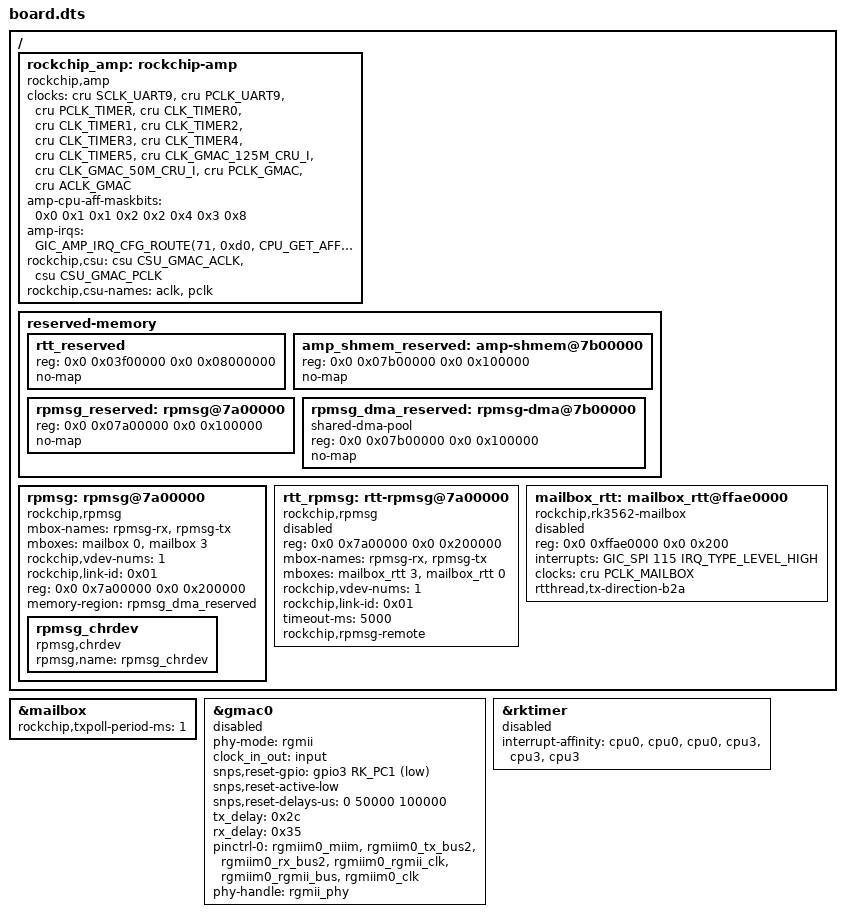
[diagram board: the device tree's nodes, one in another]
/**
 * RT-Thread RuiChing
 *
 * COPYRIGHT (C) 2024-2025 Shanghai Real-Thread Electronic Technology Co., Ltd.
 * All rights reserved.
 *
 * The license and distribution terms for this file may be
 * found in the file LICENSE in this distribution.
 */
/dts-v1/;
#include "rc-pi-3562-v1_0.dtsi"

/ {

	rockchip_amp: rockchip-amp {
		compatible = "rockchip,amp";
		clocks = <&cru SCLK_UART9>, <&cru PCLK_UART9>,
		        <&cru PCLK_TIMER>, <&cru CLK_TIMER0>, <&cru CLK_TIMER1>, <&cru CLK_TIMER2>, 
				<&cru CLK_TIMER3>, <&cru CLK_TIMER4>, <&cru CLK_TIMER5>,
				<&cru CLK_GMAC_125M_CRU_I>, <&cru CLK_GMAC_50M_CRU_I>,
			 	<&cru PCLK_GMAC>, <&cru ACLK_GMAC>;
		amp-cpu-aff-maskbits = /bits/ 64 <0x0 0x1 0x1 0x2 0x2 0x4 0x3 0x8>;
		amp-irqs = /bits/ 64 <
			GIC_AMP_IRQ_CFG_ROUTE(71, 0xd0, CPU_GET_AFFINITY(3, 0))   // UART9_IRQn
			GIC_AMP_IRQ_CFG_ROUTE(102, 0xd0, CPU_GET_AFFINITY(3, 0))   // gmacirq
			GIC_AMP_IRQ_CFG_ROUTE(105, 0xd0, CPU_GET_AFFINITY(3, 0))   // gmacirq
            GIC_AMP_IRQ_CFG_ROUTE(147, 0xd0, CPU_GET_AFFINITY(3, 0))   // mailbox_bb
            GIC_AMP_IRQ_CFG_ROUTE(77, 0xd0, CPU_GET_AFFINITY(0, 0))   // timer0
            GIC_AMP_IRQ_CFG_ROUTE(78, 0xd0, CPU_GET_AFFINITY(0, 0))   // timer1
            GIC_AMP_IRQ_CFG_ROUTE(79, 0xd0, CPU_GET_AFFINITY(0, 0))   // timer2
            GIC_AMP_IRQ_CFG_ROUTE(80, 0xd0, CPU_GET_AFFINITY(3, 0))   // timer3
            GIC_AMP_IRQ_CFG_ROUTE(81, 0xd0, CPU_GET_AFFINITY(3, 0))   // timer4
            GIC_AMP_IRQ_CFG_ROUTE(82, 0xd0, CPU_GET_AFFINITY(3, 0))   // timer5
		>;

		rockchip,csu = <&csu CSU_GMAC_ACLK>, <&csu CSU_GMAC_PCLK>;
		rockchip,csu-names = "aclk", "pclk";

		status = "okay";
	};

	reserved-memory {
		#address-cells = <2>;
		#size-cells = <2>;
		ranges;

		/* remote amp core address */
		rtt_reserved {
			reg = <0x0 0x03f00000 0x0 0x08000000>;
			no-map;
		};

		/* remote amp core address */
		amp_shmem_reserved: amp-shmem@7b00000 {
			reg = <0x0 0x07b00000 0x0 0x100000>;
			no-map;
		};
		rpmsg_reserved: rpmsg@7a00000 {
			reg = <0x0 0x07a00000 0x0 0x100000>;
			no-map;
		};
		rpmsg_dma_reserved: rpmsg-dma@7b00000 {
			compatible = "shared-dma-pool";
			reg = <0x0 0x07b00000 0x0 0x100000>;
			no-map;
		};

	};

	rpmsg: rpmsg@7a00000 {
		compatible = "rockchip,rpmsg";
		mbox-names = "rpmsg-rx", "rpmsg-tx";
		mboxes = <&mailbox 0 &mailbox 3>;
		rockchip,vdev-nums = <1>;
		/* CPU3: link-id 0x03; MCU: link-id 0x04; */
		rockchip,link-id = <0x01>;
		// reg = <0x0 0x7c00000 0x0 0x20000>;
		reg = <0x0 0x7a00000 0x0 0x200000>;
		memory-region = <&rpmsg_dma_reserved>;
		status = "okay";

        rpmsg_chrdev {
            compatible = "rpmsg,chrdev";
            rpmsg,name = "rpmsg_chrdev";
            status = "okay";
        };
	};

	rtt_rpmsg: rtt-rpmsg@7a00000 {
		compatible = "rockchip,rpmsg";
		// reg = <0x3a00000 0x020000>;
		reg = <0x0 0x7a00000 0x0 0x200000>;
		mbox-names = "rpmsg-rx", "rpmsg-tx";
		// mboxes = <&mailbox2_amp 0 &mailbox0_amp 0>;
		mboxes = <&mailbox_rtt 3 &mailbox_rtt 0>;
		rockchip,vdev-nums = <1>;
		/* CPU2: link-id 0x02; */
		rockchip,link-id = <0x01>;
		timeout-ms = <5000>;
		status = "okay,rtt";
		rockchip,rpmsg-remote;
    };

	mailbox_rtt: mailbox_rtt@ffae0000 {
		compatible = "rockchip,rk3562-mailbox",
			     "rockchip,rk3368-mailbox";
		reg = <0x0 0xffae0000 0x0 0x200>;
		interrupts = <GIC_SPI 115 IRQ_TYPE_LEVEL_HIGH>;
		clocks = <&cru PCLK_MAILBOX>;
		clock-names = "pclk_mailbox";
		#mbox-cells = <1>;
		rtthread,tx-direction-b2a;
		status = "okay,rtt";
	};

};

&mailbox {
	rockchip,txpoll-period-ms = <1>;
	status = "okay";
};

&gmac0 {
	phy-mode = "rgmii";
	clock_in_out = "input";

	snps,reset-gpio = <&gpio3 RK_PC1 GPIO_ACTIVE_LOW>;
	snps,reset-active-low;
	/* Reset time is 20ms, 100ms for rtl8211f */
	snps,reset-delays-us = <0 50000 100000>;

	tx_delay = <0x2c>;
	rx_delay = <0x35>;

	pinctrl-names = "default";
	pinctrl-0 = <&rgmiim0_miim
		     &rgmiim0_tx_bus2
		     &rgmiim0_rx_bus2
		     &rgmiim0_rgmii_clk
		     &rgmiim0_rgmii_bus
			 &rgmiim0_clk>;

	phy-handle = <&rgmii_phy>;
	status = "okay,rtt";
};

&rktimer {
    interrupt-affinity = <&cpu0>, <&cpu0>, <&cpu0>, <&cpu3>, <&cpu3>, <&cpu3>;
    status = "okay,rtt";
};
